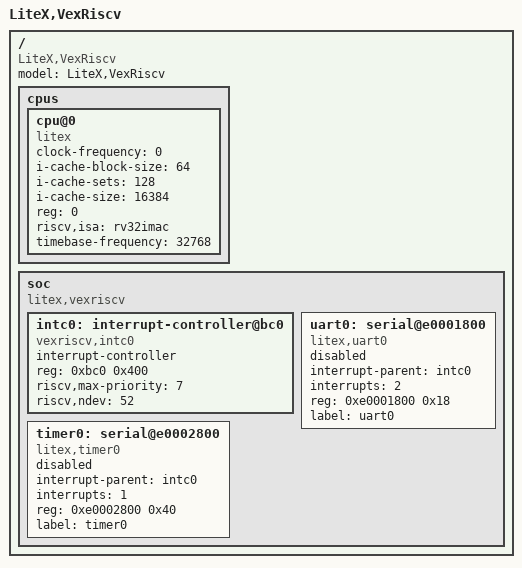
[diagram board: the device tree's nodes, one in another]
/ {
	#address-cells = <1>;
	#size-cells = <1>;
	compatible = "LiteX,VexRiscv", "litex-dev";
	model = "LiteX,VexRiscv";
	cpus {
		#address-cells = <1>;
		#size-cells = <0>;
		cpu@0 {
			clock-frequency = <0>;
			compatible = "litex", "riscv";
			device_type = "cpu";
			i-cache-block-size = <64>;
			i-cache-sets = <128>;
			i-cache-size = <16384>;
			reg = <0>;
			riscv,isa = "rv32imac";
			status = "okay";
			timebase-frequency = <32768>;
		};
	};
	soc {
		#address-cells = <1>;
		#size-cells = <1>;
        compatible = "litex,vexriscv";
		ranges;
		intc0: interrupt-controller@bc0 {
			#interrupt-cells = <1>;
			compatible = "vexriscv,intc0";
			interrupt-controller;
			reg = <0xbc0 0x400>;
			reg-names = "control";
			riscv,max-priority = <7>;
			riscv,ndev = <52>;
		};
		uart0: serial@e0001800 {
			compatible = "litex,uart0";
			interrupt-parent = <&intc0>;
			interrupts = <2>;
			reg = <0xe0001800 0x18>;
			reg-names = "control";
			label = "uart0";
			status = "disabled";
		};
        timer0: serial@e0002800 {
            compatible = "litex,timer0";
            interrupt-parent = <&intc0>;
            interrupts = <1>;
            reg = <0xe0002800 0x40>;
            reg-names = "control";
            label = "timer0";
            status = "disabled";
        };
	};
};
